# M4L1 register map
File version: 0.1
Registers are 32-bit, read-write, reset 0x0 unless marked. A register's access mark holds for its fields unless they carry their own. Offsets are from the block's base; [hi:lo] are bit positions; {n}, {i} and the like mark numbered series.

## PA — Port A
Base 0x40080000
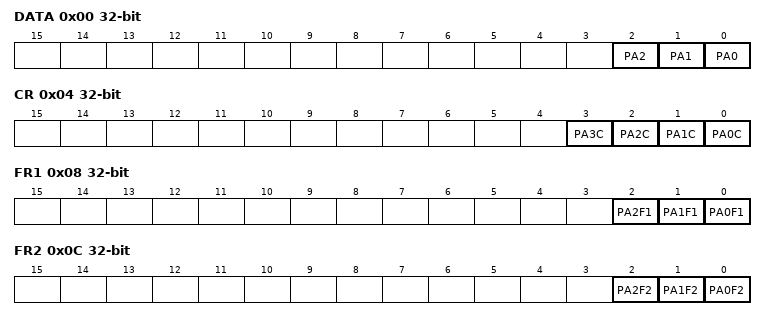
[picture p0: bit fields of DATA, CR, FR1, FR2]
0x00 DATA — Port A Data Register
  [2] PA2, [1] PA1, [0] PA0
0x04 CR — Port A Output Control Register
  [n] PA{n}C (n=0..3)
0x08 FR1 — Port A Function Register 1
  [2] PA2F1, [1] PA1F1, [0] PA0F1
0x0C FR2 — Port A Function Register 2
  [2] PA2F2, [1] PA1F2, [0] PA0F2
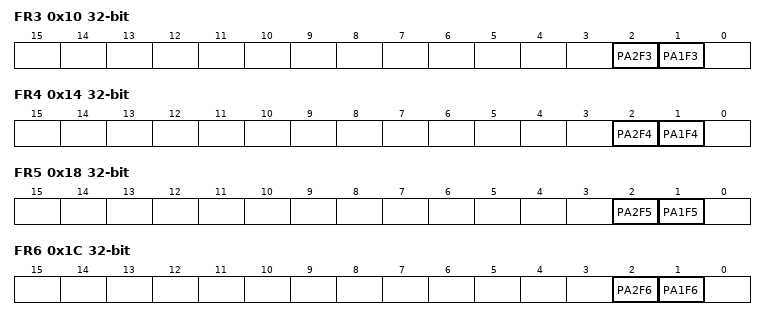
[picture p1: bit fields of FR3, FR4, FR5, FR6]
0x10 FR3 — Port A Function Register 3
  [2] PA2F3, [1] PA1F3
0x14 FR4 — Port A Function Register 3
  [2] PA2F4, [1] PA1F4
0x18 FR5 — Port A Function Register 5
  [2] PA2F5, [1] PA1F5
0x1C FR6 — Port A Function Register 6
  [2] PA2F6, [1] PA1F6
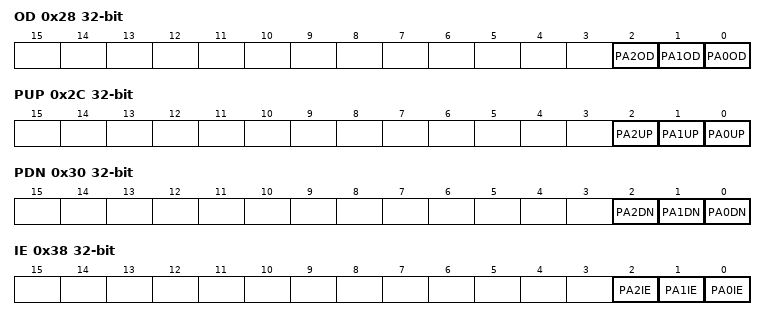
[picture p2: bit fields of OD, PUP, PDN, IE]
0x28 OD — Port A Open Drain Control Register
  [2] PA2OD, [1] PA1OD, [0] PA0OD
0x2C PUP — Port A Pull-up Control Register
  [2] PA2UP, [1] PA1UP, [0] PA0UP
0x30 PDN — Port A Pull-down Control Register
  [2] PA2DN, [1] PA1DN, [0] PA0DN
0x38 IE — Port A Input Control Register
  [2] PA2IE, [1] PA1IE, [0] PA0IE

## PB — Port B
Base 0x40080100
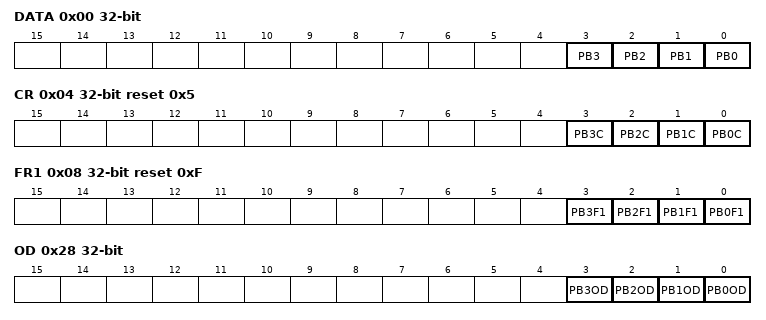
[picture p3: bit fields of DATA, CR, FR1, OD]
0x00 DATA — Port B Data Register
  [n] PB{n} (n=0..3)
0x04 CR reset 0x5 — Port B Output Control Register
  [n] PB{n}C (n=0..3)
0x08 FR1 reset 0xF — Port A Function Register 1
  [n] PB{n}F1 (n=0..3)
0x28 OD — Port B Open Drain Control Register
  [n] PB{n}OD (n=0..3)
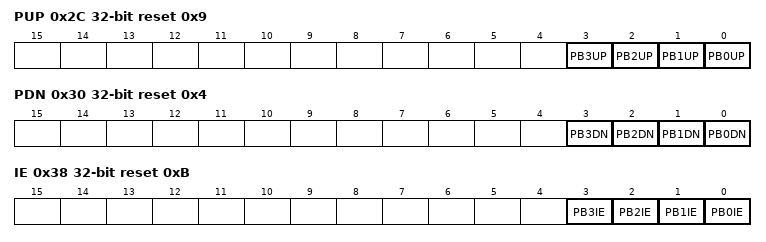
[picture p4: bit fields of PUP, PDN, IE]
0x2C PUP reset 0x9 — Port B Pull-up Control Register
  [n] PB{n}UP (n=0..3)
0x30 PDN reset 0x4 — Port B Pull-down Control Register
  [n] PB{n}DN (n=0..3)
0x38 IE reset 0xB — Port B Input Control Register
  [n] PB{n}IE (n=0..3)

## PC — Port C
Base 0x40080200
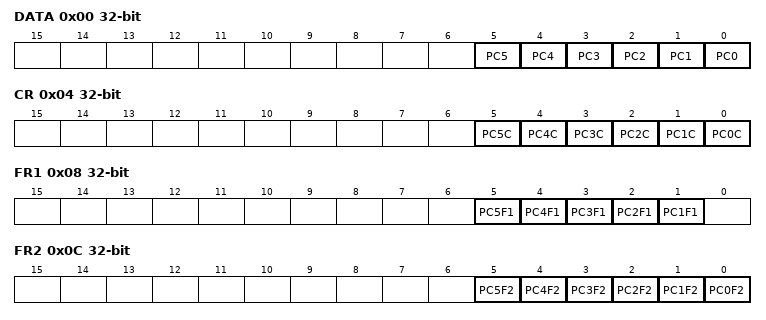
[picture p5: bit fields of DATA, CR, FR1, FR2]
0x00 DATA — Port C Data Register
  [n] PC{n} (n=0..5)
0x04 CR — Port C Output Control Register
  [n] PC{n}C (n=0..5)
0x08 FR1 — Port C Function Register 1
  [n] PC{n}F1 (n=1..5)
0x0C FR2 — Port C Function Register 1
  [n] PC{n}F2 (n=0..5)
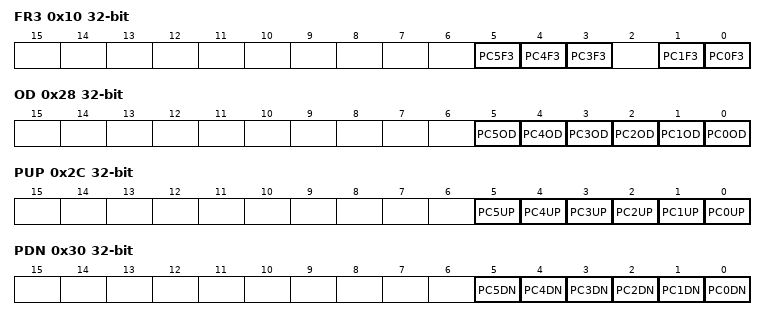
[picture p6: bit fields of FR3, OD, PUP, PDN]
0x10 FR3 — Port C Function Register 3
  [5] PC5F3, [4] PC4F3, [3] PC3F3, [1] PC1F3, [0] PC0F3
0x14 FR4 — Port C Function Register 3
  [3] PC3F4
0x28 OD — Port C Open Drain Control Register
  [n] PC{n}OD (n=0..5)
0x2C PUP — Port C Pull-up Control Register
  [n] PC{n}UP (n=0..5)
0x30 PDN — Port C Pull-down Control Register
  [n] PC{n}DN (n=0..5)
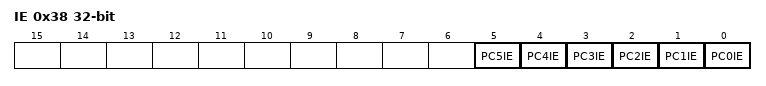
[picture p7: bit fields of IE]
0x38 IE — Port C Input Control Register
  [n] PC{n}IE (n=0..5)

## PD — Port D
Base 0x40080300
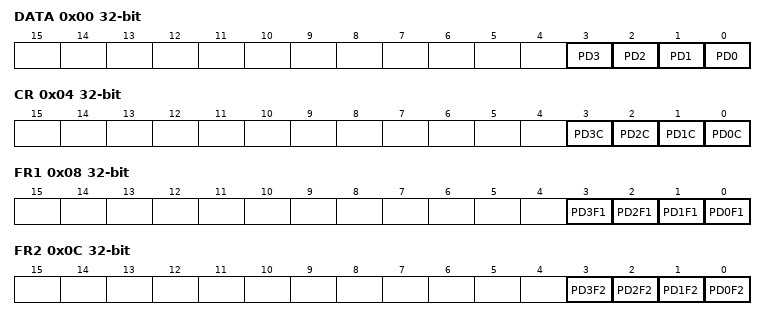
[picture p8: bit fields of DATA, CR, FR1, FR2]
0x00 DATA — Port D Data Register
  [n] PD{n} (n=0..3)
0x04 CR — Port D Output Control Register
  [n] PD{n}C (n=0..3)
0x08 FR1 — Port D Function Register 1
  [n] PD{n}F1 (n=0..3)
0x0C FR2 — Port D Function Register 2
  [n] PD{n}F2 (n=0..3)
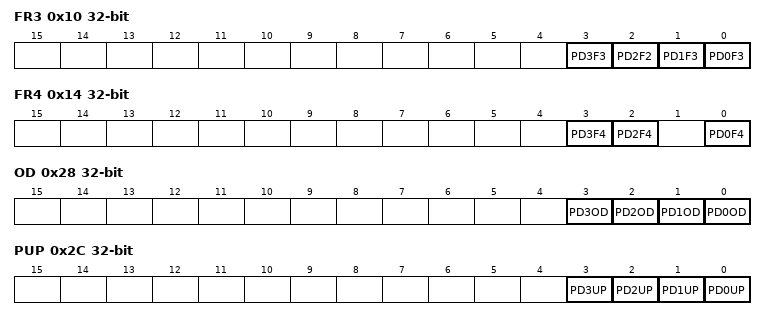
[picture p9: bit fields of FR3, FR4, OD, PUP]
0x10 FR3 — Port D Function Register 3
  [3] PD3F3, [2] PD2F2, [1] PD1F3, [0] PD0F3
0x14 FR4 — Port D Function Register 4
  [3] PD3F4, [2] PD2F4, [0] PD0F4
0x28 OD — Port D Open Drain Control Register
  [n] PD{n}OD (n=0..3)
0x2C PUP — Port D Pull-up Control Register
  [n] PD{n}UP (n=0..3)
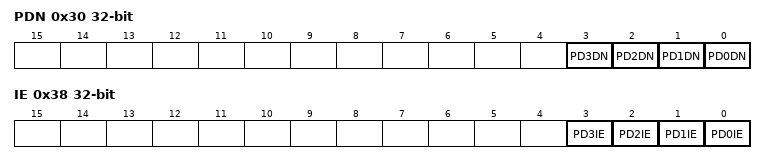
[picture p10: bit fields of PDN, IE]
0x30 PDN — Port D Pull-down Control Register
  [n] PD{n}DN (n=0..3)
0x38 IE — Port D Input Control Register
  [n] PD{n}IE (n=0..3)

## PE — Port E
Base 0x40080400
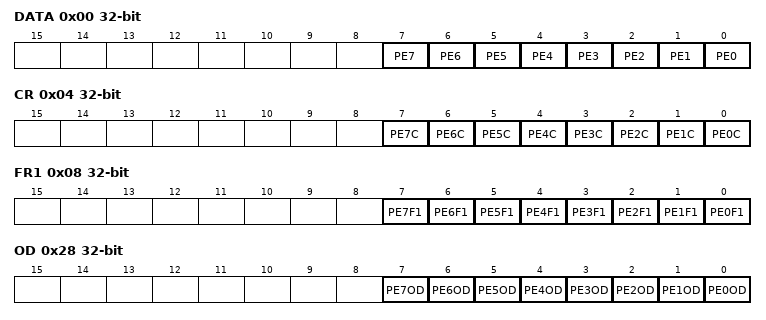
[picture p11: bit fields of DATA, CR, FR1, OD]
0x00 DATA — Port E Data Register
  [n] PE{n} (n=0..7)
0x04 CR — Port E Output Control Register
  [n] PE{n}C (n=0..7)
0x08 FR1 — Port E Function Register 1
  [n] PE{n}F1 (n=0..7)
0x28 OD — Port E Open Drain Control Register
  [n] PE{n}OD (n=0..7)
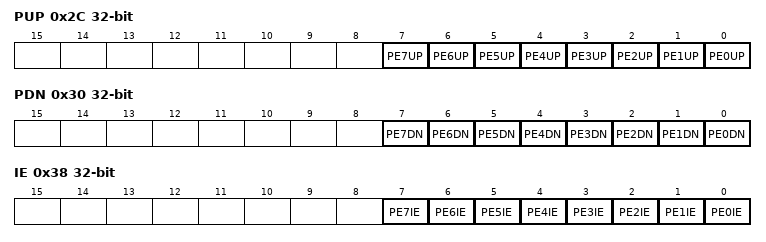
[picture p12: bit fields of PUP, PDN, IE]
0x2C PUP — Port E Pull-up Control Register
  [n] PE{n}UP (n=0..7)
0x30 PDN — Port E Pull-down Control Register
  [n] PE{n}DN (n=0..7)
0x38 IE — Port E Input Control Register
  [n] PE{n}IE (n=0..7)

## PF — Port F
Base 0x40080500
0x00 DATA — Port F Data Register
  [0] PF0
0x04 CR — Port F Output Control Register
  [0] PF0C
0x28 OD — Port F Open Drain Control Register
  [0] PF0OD
0x2C PUP — Port F Pull-up Control Register
  [0] PF0UP
0x30 PDN — Port F Pull-down Control Register
  [0] PF0DN
0x38 IE — Port F Input Control Register
  [0] PF0IE

## PG — Port G
Base 0x40080600
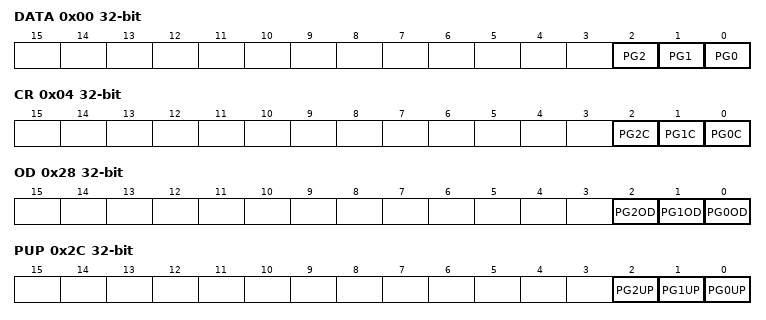
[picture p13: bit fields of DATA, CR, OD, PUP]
0x00 DATA — Port G Data Register
  [2] PG2, [1] PG1, [0] PG0
0x04 CR — Port G Output Control Register
  [2] PG2C, [1] PG1C, [0] PG0C
0x28 OD — Port G Open Drain Control Register
  [2] PG2OD, [1] PG1OD, [0] PG0OD
0x2C PUP — Port G Pull-up Control Register
  [2] PG2UP, [1] PG1UP, [0] PG0UP
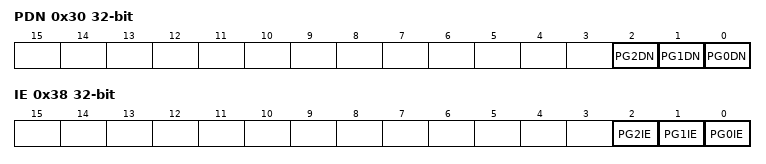
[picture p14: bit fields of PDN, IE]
0x30 PDN — Port G Pull-down Control Register
  [2] PG2DN, [1] PG1DN, [0] PG0DN
0x38 IE — Port G Input Control Register
  [2] PG2IE, [1] PG1IE, [0] PG0IE
